# STM32C5A3 register map
File version: 2.1.0
CPU: CM33 r0p4, little endian, MPU, FPU, 4 interrupt priority bits
Registers are 32-bit, read-write, reset 0x0 unless marked. A register's access mark holds for its fields unless they carry their own. Offsets are from the block's base; [hi:lo] are bit positions; {n}, {i} and the like mark numbered series; 'fields as' and 'values as' point back to an identical list.

## RCC — RCC register block
Base 0x44020C00
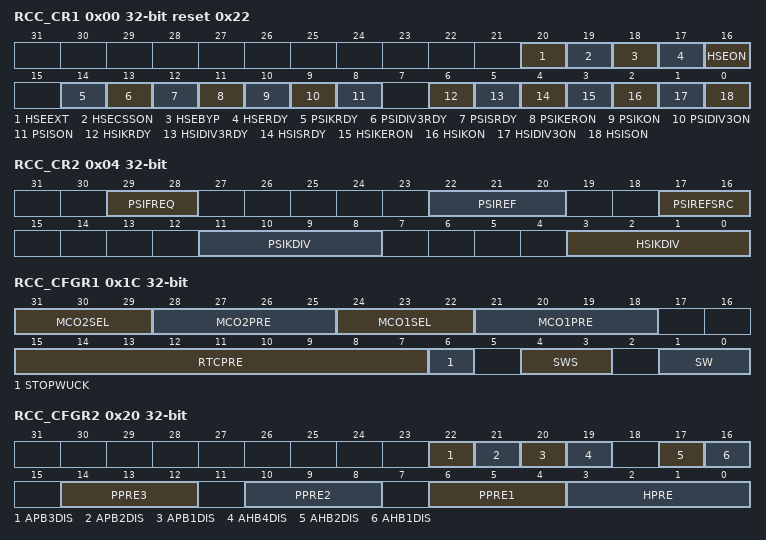
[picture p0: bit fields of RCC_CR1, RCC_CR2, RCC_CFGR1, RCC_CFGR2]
0x00 RCC_CR1 reset 0x22 — RCC clock control register
  [20] HSEEXT — External high speed clock type in Bypass mode
    0=HSE in analog mode (default after reset); 1=HSE in digital mode
  [19] HSECSSON — HSE clock security system enable
    0=CSS on HSE off (clock detector off) (default after reset); 1=CSS on HSE on (clock detector on if the HSE oscillator is stable, off if not)
  [18] HSEBYP — HSE clock bypass
    0=HSE oscillator not bypassed (default after reset); 1=HSE oscillator bypassed with an external clock
  [17] HSERDY ro — HSE clock ready flag
    0=HSE clock not ready (default after reset); 1=HSE clock ready
  [16] HSEON — HSE clock enable
    0=HSE off (default after reset); 1=HSE on
  [14] PSIKRDY ro — PSIK clock ready flag
    0=PSIK clock not ready (default after reset); 1=PSIK clock ready
  [13] PSIDIV3RDY ro — PSIDIV3 clock ready flag
    0=PSIDIV3 clock not ready (default after reset); 1=PSIDIV3 clock ready
  [12] PSISRDY ro — PSIS clock ready flag
    0=PSIS clock not ready (default after reset); 1=PSIS clock ready
  [11] PSIKERON — PSI clock enable in Stop mode
    0=No effect on PSI (default after reset); 1=PSI forced to on even in Stop 0 mode
  [10] PSIKON — PSIK clock enable
    0=PSIK off (default after reset); 1=PSIK on
  [9] PSIDIV3ON — PSIDIV3 clock enable
    0=PSIDIV3 off (default after reset); 1=PSIDIV3 on
  [8] PSISON — PSIS clock enable
    0=PSIS off (default after reset); 1=PSIS on
  [6] HSIKRDY ro — HSIK clock ready flag
    0=HSIK clock not ready (default after reset); 1=HSIK clock ready
  [5] HSIDIV3RDY ro — HSIDIV3 clock ready flag
    0=HSIDIV3 clock not ready (default after reset); 1=HSIDIV3 clock ready
  [4] HSISRDY ro — HSIS clock ready flag
    0=HSIS clock not ready (default after reset); 1=HSIS clock ready
  [3] HSIKERON — HSI clock enable in Stop mode
    0=No effect on HSI (default after reset); 1=HSI forced to on even in Stop 0 mode
  [2] HSIKON — HSIK clock enable
    0=HSIK off (default after reset); 1=HSIK on
  [1] HSIDIV3ON — HSIDIV3 clock enable
    0=HSIDIV3 off; 1=HSIDIV3 on (default after reset)
  [0] HSISON — HSIS clock enable
    0=HSIS off (default after reset); 1=HSIS on
0x04 RCC_CR2 — RCC clock control register
  [29:28] PSIFREQ — PSI target frequency configuration
    0=PSI nominal frequency = 100 MHz; 1=PSI nominal frequency = 144 MHz
  [22:20] PSIREF — PSI reference clock frequency selection
    0=32; 1=8 MHz; 2=16 MHz; 3=24 MHz; 4=25 MHz; 5=32 MHz; 6=48 MHz; 7=50 MHz
  [17:16] PSIREFSRC — PSI reference clock source selection
    0=HSE clock used as reference for PSI; 1=LSE clock used as reference for PSI; 2=HSI clock divided by 18 used as reference for PSI
  [11:8] PSIKDIV — PSI clock out divider factor
    0=PSI clock divided by 1; 1=PSI clock divided by 1; 2=PSI clock divided by 1; 3=PSI clock divided by 2; 4=PSI clock divided by 2; 14=PSI clock divided by 7; 15=PSI clock divided by 8
  [3:0] HSIKDIV — HSI clock out divider factor
    0=HSI clock divided by 1; 1=HSI clock divided by 1; 2=HSI clock divided by 1; 3=HSI clock divided by 2; 4=HSI clock divided by 2; 14=HSI clock divided by 7; 15=HSI clock divided by 8
0x1C RCC_CFGR1 — RCC clock configuration register1
  [31:29] MCO2SEL — Microcontroller clock output 2
    0=system clock selected (sys_ck) (default after reset); 1=HSE clock selected (hse_ck); 2=LSE clock selected (lse_ck); 3=LSI clock selected (lsi_ck); 4=PSIK clock selected (psik_ck); 5=HSIK clock selected (hsik_ck); 6=PSIDIV3 clock selected (psidiv3_ck); 7=HSIDIV3 clock selected (hsidiv3_ck)
  [28:25] MCO2PRE — MCO2 prescaler
    0=Prescaler disabled (default after reset); 1=Division by 1 (bypass); 2=Division by 2; 3=Division by 3; 4=Division by 4; 15=Division by 15
  [24:22] MCO1SEL — Microcontroller clock output 1
    0=System clock selected (sys_ck) (default after reset); 1=HSE clock selected (hse_ck); 2=LSE clock selected (lse_ck); 3=LSI clock selected (lsi_ck); 4=PSIK clock selected (psik_ck); 5=HSIK clock selected (hsik_ck); 6=PSIS clock selected (psis_ck); 7=HSIS clock selected (hsis_ck)
  [21:18] MCO1PRE — MCO1 prescaler
    values as MCO2PRE
  [15:7] RTCPRE — HSE division factor for RTC clock (source of HSE_1MHz clock)
    0=No clock (default after reset); 1=No clock; 2=HSE/2; 3=HSE/3; 4=HSE/4; 0x1FE=HSE/510; 0x1FF=HSE/511
  [6] STOPWUCK — System clock selection after a wake-up from system Stop mode
    0=HSIDIV3 selected as wake-up clock from system Stop mode (default after reset); 1=HSIS selected as wake-up clock from system Stop mode
  [4:3] SWS ro — System clock switch status
    0=HSIDIV3 used as system clock (hsidiv3_ck) (default after reset); 1=HSIS used as system clock (hsis_ck); 2=HSE used as system clock (hse_ck); 3=PSIS used as system clock (psis_ck)
  [1:0] SW — System clock and trace clock switch
    0=HSIDIV3 selected as system clock (hsidiv3_ck) (default after reset); 1=HSIS selected as system clock (hsis_ck); 2=HSE selected as system clock (hse_ck); 3=PSIS selected as system clock (psis_ck)
0x20 RCC_CFGR2 — RCC CPU domain clock configuration register 2
  [22] APB3DIS — APB3 clock disable value.
    0=APB3 clock enabled, distributed to peripherals according to their dedicated clock enable control bits; 1=APB3 clock disabled
  [21] APB2DIS — APB2 clock disable value
    0=APB2 clock enabled, distributed to peripherals according to their dedicated clock enable control bits; 1=APB2 clock disabled
  [20] APB1DIS — APB1 clock disable value
    0=APB1 clock enabled, distributed to peripherals according to their dedicated clock enable control bits; 1=APB1 clock disabled
  [19] AHB4DIS — AHB4 clock disable
    0=AHB4 clock enabled, distributed to peripherals according to their dedicated clock enable control bits; 1=AHB4 clock disabled
  [17] AHB2DIS — AHB2 clock disable
    0=AHB2 clock enabled, distributed to peripherals according to their dedicated clock enable control bits; 1=AHB2 clock disabled
  [16] AHB1DIS — AHB1 clock disable
    0=AHB1 clock enabled, distributed to peripherals according to their dedicated clock enable control bits; 1=AHB1 clock disabled
  [14:12] PPRE3 — APB low-speed prescaler (APB3)
    4=rcc_pclk3 = rcc_hclk1 / 2; 5=rcc_pclk3 = rcc_hclk1 / 4; 6=rcc_pclk3 = rcc_hclk1 / 8; 7=rcc_pclk3 = rcc_hclk1 / 16
  [10:8] PPRE2 — APB high-speed prescaler (APB2)
    4=rcc_pclk2 = rcc_hclk1 / 2; 5=rcc_pclk2 = rcc_hclk1 / 4; 6=rcc_pclk2 = rcc_hclk1 / 8; 7=rcc_pclk2 = rcc_hclk1 / 16
  [6:4] PPRE1 — APB low-speed prescaler (APB1)
    4=rcc_pclk1 = rcc_hclk1 / 2; 5=rcc_pclk1 = rcc_hclk1 / 4; 6=rcc_pclk1 = rcc_hclk1 / 8; 7=rcc_pclk1 = rcc_hclk1 / 16
  [3:0] HPRE — AHB prescaler
    8=rcc_hclk = sys_ck / 2; 9=rcc_hclk = sys_ck / 4; 10=rcc_hclk = sys_ck / 8; 11=rcc_hclk = sys_ck / 16; 12=rcc_hclk = sys_ck / 64; 13=rcc_hclk = sys_ck / 128; 14=rcc_hclk = sys_ck / 256; 15=rcc_hclk = sys_ck / 512
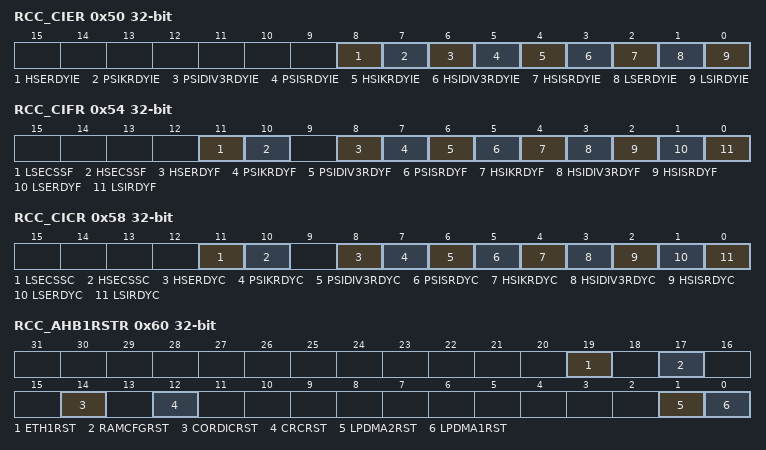
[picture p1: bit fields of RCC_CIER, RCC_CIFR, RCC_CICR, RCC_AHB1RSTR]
0x50 RCC_CIER — RCC clock source interrupt enable register
  [8] HSERDYIE — HSE ready interrupt enable
    0=HSE ready interrupt disabled (default after reset); 1=HSE ready interrupt enabled
  [7] PSIKRDYIE — PSIK ready interrupt enable
    0=PSIK ready interrupt disabled (default after reset); 1=PSIK ready interrupt enabled
  [6] PSIDIV3RDYIE — PSIDIV3 ready interrupt enable
    0=PSIDIV3 ready interrupt disabled (default after reset); 1=PSIDIV3 ready interrupt enabled
  [5] PSISRDYIE — PSIS ready interrupt enable
    0=PSI ready interrupt disabled (default after reset); 1=PSI ready interrupt enabled
  [4] HSIKRDYIE — HSIK ready interrupt enable
    0=HSIK ready interrupt disabled (default after reset); 1=HSIK ready interrupt enabled
  [3] HSIDIV3RDYIE — HSIDIV3 ready interrupt enable
    0=HSIDIV3 ready interrupt disabled (default after reset); 1=HSIDIV3 ready interrupt enabled
  [2] HSISRDYIE — HSIS ready interrupt enable
    0=HSI ready interrupt disabled (default after reset); 1=HSI ready interrupt enabled
  [1] LSERDYIE — LSE ready interrupt enable
    0=LSE ready interrupt disabled (default after reset); 1=LSE ready interrupt enabled
  [0] LSIRDYIE — LSI ready interrupt enable
    0=LSI ready interrupt disabled (default after reset); 1=LSI ready interrupt enabled
0x54 RCC_CIFR ro — RCC clock source interrupt flag register
  [11] LSECSSF — LSE clock security system interrupt flag
    0=No clock security interrupt caused by LSE clock failure (default after reset); 1=Clock security interrupt caused by LSE clock failure
  [10] HSECSSF — HSE clock security system interrupt flag
    0=No clock security interrupt caused by HSE clock failure (default after reset); 1=Clock security interrupt caused by HSE clock failure
  [8] HSERDYF — HSE ready interrupt flag
    0=No clock ready interrupt caused by the HSE (default after reset); 1=Clock ready interrupt caused by the HSE
  [7] PSIKRDYF — PSIK ready interrupt flag
    0=No clock ready interrupt caused by PSIK (default after reset); 1=Clock ready interrupt caused by PSIK
  [6] PSIDIV3RDYF — PSIDIV3 ready interrupt flag
    0=No clock ready interrupt caused by PSIDIV3 (default after reset); 1=Clock ready interrupt caused by PSIDIV3
  [5] PSISRDYF — PSIS ready interrupt flag
    0=No clock ready interrupt caused by PSIS (default after reset); 1=Clock ready interrupt caused by PSIS
  [4] HSIKRDYF — HSIK ready interrupt flag
    0=No clock ready interrupt caused by HSIK (default after reset); 1=Clock ready interrupt caused by HSIK
  [3] HSIDIV3RDYF — HSIDIV3 ready interrupt flag
    0=No clock ready interrupt caused by HSIDIV3 (default after reset); 1=Clock ready interrupt caused by HSIDIV3
  [2] HSISRDYF — HSIS ready interrupt flag
    0=No clock ready interrupt caused by HSIS (default after reset); 1=Clock ready interrupt caused by HSIS
  [1] LSERDYF — LSE ready interrupt flag
    0=No clock ready interrupt caused by the LSE (default after reset); 1=Clock ready interrupt caused by the LSE
  [0] LSIRDYF — LSI ready interrupt flag
    0=No clock ready interrupt caused by the LSI (default after reset); 1=Clock ready interrupt caused by the LSI
0x58 RCC_CICR — RCC clock source interrupt clear register
  [11] LSECSSC — LSE clock security system interrupt clear
    0=LSECSSF no effect (default after reset); 1=LSECSSF cleared
  [10] HSECSSC — HSE clock security system interrupt clear
    0=HSECSSF no effect (default after reset); 1=HSECSSF cleared
  [8] HSERDYC — HSE ready interrupt clear
    0=HSERDYF no effect (default after reset); 1=HSERDYF cleared
  [7] PSIKRDYC — PSIK ready interrupt clear
    0=PSIKRDYF no effect (default after reset); 1=PSIKRDYF cleared
  [6] PSIDIV3RDYC — PSIDIV3 ready interrupt clear
    0=PSIDIV3RDYF no effect (default after reset); 1=PSIDIV3RDYF cleared
  [5] PSISRDYC — PSIS ready interrupt clear
    0=PSISRDYF no effect (default after reset); 1=PSISRDYF cleared
  [4] HSIKRDYC — HSIK ready interrupt clear
    0=HSIKRDYF no effect (default after reset); 1=HSIKRDYF cleared
  [3] HSIDIV3RDYC — HSIDIV3 ready interrupt clear
    0=HSIDIV3RDYF no effect (default after reset); 1=HSIDIV3RDYF cleared
  [2] HSISRDYC — HSIS ready interrupt clear
    0=HSISRDYF no effect (default after reset); 1=HSISRDYF cleared
  [1] LSERDYC — LSE ready interrupt clear
    0=LSERDYF no effect (default after reset); 1=LSERDYF cleared
  [0] LSIRDYC — LSI ready interrupt clear
    0=LSIRDYF no effect (default after reset); 1=LSIRDYF cleared
0x60 RCC_AHB1RSTR — RCC AHB1 reset register
  [19] ETH1RST — ETHERNET reset
    0=ETHERNET not reset (default after reset); 1=ETHERNET reset
  [17] RAMCFGRST — RAMCFG reset
    0=RAMCFG not reset (default after reset); 1=RAMCFG reset
  [14] CORDICRST — CORDIC reset
    0=CORDIC not reset (default after reset); 1=CORDIC reset
  [12] CRCRST — CRC reset
    0=CRC not reset (default after reset); 1=CRC reset
  [1] LPDMA2RST — LPDMA2 reset
    0=LPDMA2 not reset (default after reset); 1=LPDMA2 reset
  [0] LPDMA1RST — LPDMA1 reset
    0=LPDMA1 not reset (default after reset); 1=LPDMA1 reset
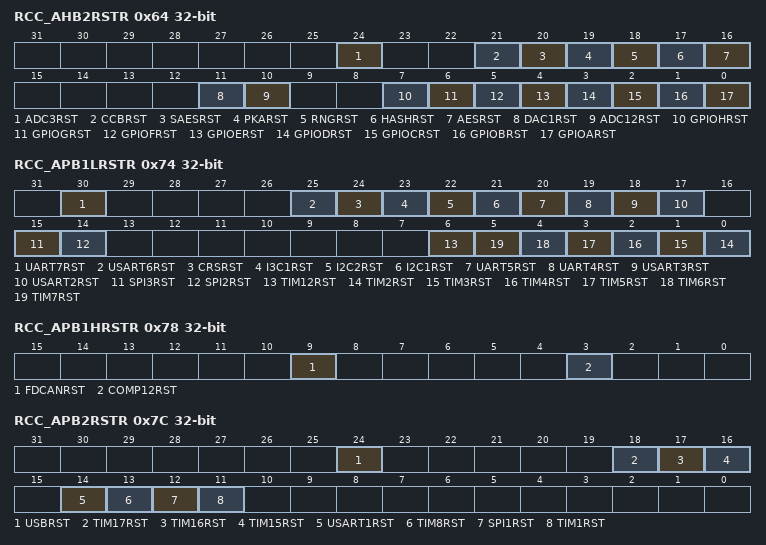
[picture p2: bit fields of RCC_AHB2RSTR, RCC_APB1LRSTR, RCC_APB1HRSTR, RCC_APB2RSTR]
0x64 RCC_AHB2RSTR — RCC AHB2 peripheral reset register
  [24] ADC3RST — ADC3 reset
    0=ADC3 not reset (default after reset); 1=ADC3 reset
  [21] CCBRST — CCB reset
    0=CCB not reset (default after reset); 1=CCB reset
  [20] SAESRST — SAES reset
    0=SAES not reset (default after reset); 1=SAES reset
  [19] PKARST — PKA reset
    0=PKA not reset (default after reset); 1=PKA reset
  [18] RNGRST — RNG reset
    0=RNG not reset (default after reset); 1=RNG reset
  [17] HASHRST — HASH reset
    0=HASH not reset (default after reset); 1=HASH reset
  [16] AESRST — AES reset
    0=AES not reset (default after reset); 1=AES reset
  [11] DAC1RST — DAC reset
    0=DAC not reset (default after reset); 1=DAC reset
  [10] ADC12RST — ADC1 and ADC2 reset
    0=ADC1 and ADC2 not reset (default after reset); 1=ADC1 and ADC2 reset
  [7] GPIOHRST — GPIOH reset
    0=GPIOH not reset (default after reset); 1=GPIOH reset
  [6] GPIOGRST — GPIOG reset
    0=GPIOG not reset (default after reset); 1=GPIOG reset
  [5] GPIOFRST — GPIOF reset
    0=GPIOF not reset (default after reset); 1=GPIOF reset
  [4] GPIOERST — GPIOE reset
    0=GPIOE not reset (default after reset); 1=GPIOE reset
  [3] GPIODRST — GPIOD reset
    0=e GPIOD not reset (default after reset); 1=GPIOD reset
  [2] GPIOCRST — GPIOC reset
    0=GPIOC not reset (default after reset); 1=GPIOC reset
  [1] GPIOBRST — GPIOB reset
    0=GPIOB not reset (default after reset); 1=GPIOB reset
  [0] GPIOARST — GPIOA reset
    0=GPIOA not reset (default after reset); 1=GPIOA reset
0x6C RCC_AHB4RSTR — RCC AHB4 peripheral reset register
  [20] XSPI1RST — XSPI1 reset
    0=XSPI1 not reset (default after reset); 1=XSPI1 reset
0x74 RCC_APB1LRSTR — RCC APB1 peripheral low reset register
  [30] UART7RST — UART7 reset
    0=UART7 not reset (default after reset); 1=UART7 reset
  [25] USART6RST — USART6 reset
    0=USART6 not reset (default after reset); 1=USART6 reset
  [24] CRSRST — CRS reset
    0=CRS not reset (default after reset); 1=CRS reset
  [23] I3C1RST — I3C1 block reset
    0=I3C1 not reset (default after reset); 1=I3C1 reset
  [22] I2C2RST — I2C2 reset
    0=I2C2 not reset (default after reset); 1=I2C2 reset
  [21] I2C1RST — I2C1 reset
    0=I2C1 not reset (default after reset); 1=I2C1 reset
  [20] UART5RST — UART5 reset
    0=UART5 not reset (default after reset); 1=UART5 reset
  [19] UART4RST — UART4 reset
    0=UART4 not reset (default after reset); 1=UART4 reset
  [18] USART3RST — USART3 reset
    0=USART3 not reset (default after reset); 1=USART3 reset
  [17] USART2RST — USART2 reset
    0=USART2 not reset (default after reset); 1=USART2 reset
  [15] SPI3RST — SPI3 reset
    0=SPI3 not reset (default after reset); 1=SPI3 reset
  [14] SPI2RST — SPI2 reset
    0=SPI2 not reset (default after reset); 1=SPI2 reset
  [6] TIM12RST — TIM12 reset
    0=TIM12 not reset (default after reset); 1=TIM12 reset
  [n-2] TIM{n}RST (n=2..7) — TIM{n} reset
    0=TIM{n} not reset (default after reset); 1=TIM{n} reset
0x78 RCC_APB1HRSTR — RCC APB1peripheral high reset register
  [9] FDCANRST — FDCAN1 and FDCAN2 reset
    0=FDCAN1 and FDCAN2 not reset (default after reset); 1=FDCAN1 and FDCAN2 reset
  [3] COMP12RST — COMP reset
    0=COMP not reset (default after reset); 1=COMP reset
0x7C RCC_APB2RSTR — RCC APB2 peripheral reset register
  [24] USBRST — USB reset
    0=USB not reset (default after reset); 1=USB reset
  [18] TIM17RST — TIM17 reset
    0=TIM17 not reset (default after reset); 1=TIM17 reset
  [17] TIM16RST — TIM16 reset
    0=TIM16 not reset (default after reset); 1=TIM16 reset
  [16] TIM15RST — TIM15 reset
    0=TIM15 not reset (default after reset); 1=TIM15 reset
  [14] USART1RST — USART1 reset
    0=USART1 not reset (default after reset); 1=USART1 reset
  [13] TIM8RST — TIM8 reset
    0=TIM8 not reset (default after reset); 1=TIM8 reset
  [12] SPI1RST — SPI1 reset
    0=SPI1 not reset (default after reset); 1=SPI1 reset
  [11] TIM1RST — TIM1 reset
    0=TIM1 not reset (default after reset); 1=TIM1 reset
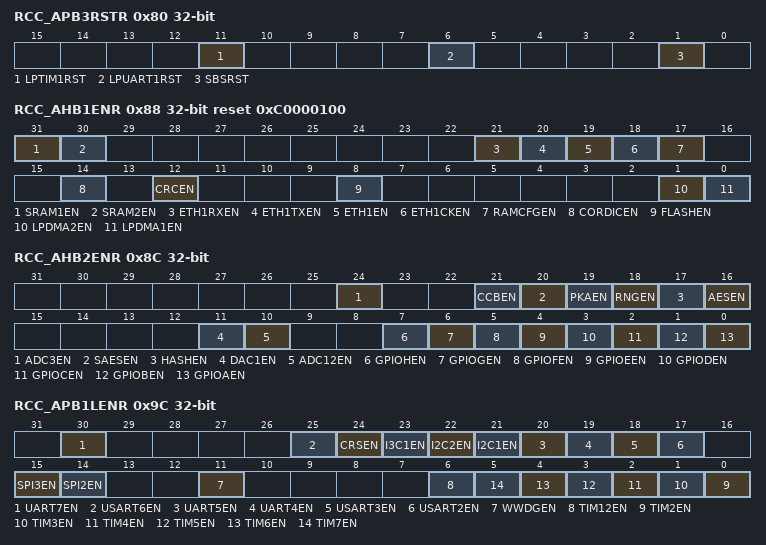
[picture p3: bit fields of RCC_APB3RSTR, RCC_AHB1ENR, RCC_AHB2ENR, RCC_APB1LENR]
0x80 RCC_APB3RSTR — RCC APB3 peripheral reset register
  [11] LPTIM1RST — LPTIM1 reset
    0=LPTIM1 not reset (default after reset); 1=LPTIM1 reset
  [6] LPUART1RST — LPUART1 reset
    0=LPUART1 not reset (default after reset); 1=LPUART1 reset
  [1] SBSRST — SBS reset
    0=SBS not reset (default after reset); 1=SBS reset
0x88 RCC_AHB1ENR reset 0xC0000100 — RCC AHB1 peripherals clock register
  [31] SRAM1EN — SRAM1 clock enable
    0=SRAM1 clock disabled; 1=SRAM1 clock enabled (default after reset)
  [30] SRAM2EN — SRAM2 clock enable
    0=SRAM2 clock disabled; 1=SRAM2 clock enabled (default after reset)
  [21] ETH1RXEN — ETHRX clock enable
    0=ETHRX clock disabled (default after reset); 1=ETHRX clock enabled
  [20] ETH1TXEN — ETHTX clock enable
    0=ETHTX clock disabled (default after reset); 1=ETHTX clock enabled
  [19] ETH1EN — ETH clock enable
    0=ETH clock disabled (default after reset); 1=ETH clock enabled
  [18] ETH1CKEN — ETH internal clock enable
    0=ETH internal clock disabled (default after reset); 1=ETH internal clock enabled
  [17] RAMCFGEN — RAMCFG clock enable
    0=RAMCFG clock disabled (default after reset); 1=RAMCFG clock enabled
  [14] CORDICEN — CORDIC clock enable
    0=CORDIC clock disabled (default after reset); 1=CORDIC clock enabled
  [12] CRCEN — CRC clock enable
    0=CRC clock disabled (default after reset); 1=CRC clock enabled
  [8] FLASHEN — Flash interface clock enable
    0=FLASH clock disabled; 1=FLASH clock enabled (default after reset)
  [1] LPDMA2EN — LPDMA2 clock enable
    0=LPDMA2 clock disabled (default after reset); 1=LPDMA2 clock enabled
  [0] LPDMA1EN — LPDMA1 clock enable
    0=LPDMA1 clock disabled (default after reset); 1=LPDMA1 clock enabled
0x8C RCC_AHB2ENR — RCC AHB2 peripheral clock register
  [24] ADC3EN — ADC3 clock enable
    0=ADC3 clock disabled (default after reset); 1=ADC3 clock enabled
  [21] CCBEN — CCB clock enable
    0=CCB clock disabled (default after reset); 1=CCB clock enabled
  [20] SAESEN — SAES clock enable
    0=SAES clock disabled (default after reset); 1=SAES clock enabled
  [19] PKAEN — PKA clock enable
    0=PKA clock disabled (default after reset); 1=PKA clock enabled
  [18] RNGEN — RNG clock enable
    0=RNG clock disabled (default after reset); 1=RNG clock enabled
  [17] HASHEN — HASH clock enable
    0=HASH clock disabled (default after reset); 1=HASH clock enabled
  [16] AESEN — AES clock enable
    0=AES clock disabled (default after reset); 1=AES clock enabled
  [11] DAC1EN — DAC clock enable
    0=DAC clock disabled (default after reset); 1=DAC clock enabled
  [10] ADC12EN — ADC1 and ADC2 clock enable
    0=ADC1 and ADC2 clock disabled (default after reset); 1=ADC1 and ADC2 clock enabled
  [7] GPIOHEN — GPIOH clock enable
    0=GPIOH clock disabled (default after reset); 1=GPIOH clock enabled
  [6] GPIOGEN — GPIOG clock enable
    0=GPIOG clock disabled (default after reset); 1=GPIOG clock enabled
  [5] GPIOFEN — GPIOF clock enable
    0=GPIOF clock disabled (default after reset); 1=GPIOF clock enabled
  [4] GPIOEEN — GPIOE clock enable
    0=GPIOE clock disabled (default after reset); 1=GPIOE clock enabled
  [3] GPIODEN — GPIOD clock enable
    0=GPIOD clock disabled (default after reset); 1=GPIOD clock enabled
  [2] GPIOCEN — GPIOC clock enable
    0=GPIOC clock disabled (default after reset); 1=GPIOC clock enabled
  [1] GPIOBEN — GPIOB clock enable
    0=GPIOB clock disabled (default after reset); 1=GPIOB clock enabled
  [0] GPIOAEN — GPIOA clock enable
    0=GPIOA clock disabled (default after reset); 1=GPIOA clock enabled
0x94 RCC_AHB4ENR — RCC AHB4 peripheral clock register
  [20] XSPI1EN — XSPI1 clock enable
    0=XSPI1 peripheral clock disabled; 1=XSPI1 peripheral clock enabled
0x9C RCC_APB1LENR — RCC APB1 peripheral clock register
  [30] UART7EN — UART7 clock enable
    0=UART7 clock disabled (default after reset); 1=UART7 clock enabled
  [25] USART6EN — USART6 clock enable
    0=USART6 clock disabled (default after reset); 1=USART6 clock enabled
  [24] CRSEN — CRS clock enable
    0=CRS clock disabled (default after reset); 1=CRS clock enabled
  [23] I3C1EN — I3C1 clock enable
    0=I3C1 clock disabled (default after reset); 1=I3C1 clock enabled
  [22] I2C2EN — I2C2 clock enable
    0=I2C2 clock disabled (default after reset); 1=I2C2 clock enabled
  [21] I2C1EN — I2C1 clock enable
    0=I2C1 clock disabled (default after reset); 1=I2C1 clock enabled
  [20] UART5EN — UART5 clock enable
    0=UART5 clock disabled (default after reset); 1=UART5 clock enabled
  [19] UART4EN — UART4 clock enable
    0=UART4 clock disabled (default after reset); 1=UART4 clock enabled
  [18] USART3EN — USART3 clock enable
    0=USART3 clock disabled (default after reset); 1=USART3 clock enabled
  [17] USART2EN — USART2 clock enable
    0=USART2 clock disabled (default after reset); 1=USART2 clock enabled
  [15] SPI3EN — SPI3 clock enable
    0=SPI3 clock disabled (default after reset); 1=SPI3 clock enabled
  [14] SPI2EN — SPI2 clock enable
    0=SPI2 clock disabled (default after reset); 1=SPI2 clock enabled
  [11] WWDGEN — WWDG clock enable
    0=WWDG clock disabled (default after reset); 1=WWDG clock enabled
  [6] TIM12EN — TIM12 clock enable
    0=TIM12 clock disabled (default after reset); 1=TIM12 clock enabled
  [n-2] TIM{n}EN (n=2..7) — TIM{n} clock enable
    0=TIM{n} clock disabled (default after reset); 1=TIM{n} clock enabled
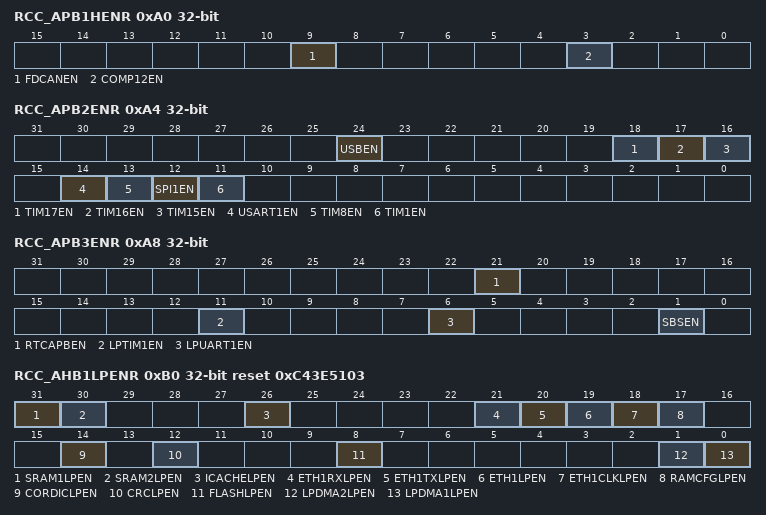
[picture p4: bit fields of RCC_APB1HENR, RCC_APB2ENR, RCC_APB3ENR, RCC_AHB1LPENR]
0xA0 RCC_APB1HENR — RCC APB1 peripheral clock register
  [9] FDCANEN — FDCAN1 and FDCAN2 clock enable
    0=FDCAN1 and FDCAN2 clock disabled (default after reset); 1=FDCAN1 and FDCAN2 clock enabled
  [3] COMP12EN — COMP clock enable
    0=COMP clock disabled (default after reset); 1=COMP clock enabled
0xA4 RCC_APB2ENR — RCC APB2 peripheral clock register
  [24] USBEN — USB clock enable
    0=USB clock disabled (default after reset); 1=USB clock enabled
  [18] TIM17EN — TIM17 clock enable
    0=TIM17 clock disabled (default after reset); 1=TIM17 clock enabled
  [17] TIM16EN — TIM16 clock enable
    0=TIM16 clock disabled (default after reset); 1=TIM16 clock enabled
  [16] TIM15EN — TIM15 clock enable
    0=TIM15 clock disabled (default after reset); 1=TIM15 clock enabled
  [14] USART1EN — USART1 clock enable
    0=USART1 clock disabled (default after reset); 1=USART1 clock enabled
  [13] TIM8EN — TIM8 clock enable
    0=TIM8 clock disabled (default after reset); 1=TIM8 clock enabled
  [12] SPI1EN — SPI1 clock enable
    0=SPI1 clock disabled (default after reset); 1=SPI1 clock enabled
  [11] TIM1EN — TIM1 clock enable
    0=TIM1 clock disabled (default after reset); 1=TIM1 clock enabled
0xA8 RCC_APB3ENR — RCC APB3 peripheral clock register
  [21] RTCAPBEN — RTC APB interface clock enable
    0=RTC APB interface clock disabled (default after reset); 1=RTC APB interface clock enabled
  [11] LPTIM1EN — LPTIM1 clock enable
    0=LPTIM1 clock disabled (default after reset); 1=LPTIM1 clock enabled
  [6] LPUART1EN — LPUART1 clock enable
    0=LPUART1 clock disabled (default after reset); 1=LPUART1 clock enabled
  [1] SBSEN — SBS clock enable
    0=SBS clock disabled (default after reset); 1=SBS clock enabled
0xB0 RCC_AHB1LPENR reset 0xC43E5103 — RCC AHB1 sleep clock register
  [31] SRAM1LPEN — SRAM1 clock enable during Sleep mode
    0=SRAM1 clock disabled during Sleep mode; 1=SRAM1 clock enabled during Sleep mode (default after reset)
  [30] SRAM2LPEN — SRAM2 clock enable during Sleep mode
    0=SRAM2 clock disabled during Sleep mode; 1=SRAM2 clock enabled during Sleep mode (default after reset)
  [26] ICACHELPEN — ICACHE clock enable during Sleep mode
    0=ICACHE clock disabled during Sleep mode; 1=ICACHE clock enabled during Sleep mode (default after reset)
  [21] ETH1RXLPEN — ETHRX clock enable during Sleep mode
    0=ETHRX clock disabled during Sleep mode; 1=ETHRX clock enabled during Sleep mode (default after reset)
  [20] ETH1TXLPEN — ETHTX clock enable during Sleep mode
    0=ETHTX clock disabled during Sleep mode; 1=ETHTX clock enabled during Sleep mode (default after reset)
  [19] ETH1LPEN — ETH clock enable during Sleep mode
    0=ETH clock disabled during Sleep mode; 1=ETH clock enabled during Sleep mode (default after reset)
  [18] ETH1CLKLPEN — ETH internal clock enable during Sleep mode
    0=ETH internal clock disabled during Sleep mode; 1=ETH internal clock enabled during Sleep mode (default after reset)
  [17] RAMCFGLPEN — RAMCFG clock enable during Sleep mode
    0=RAMCFG clock disabled during Sleep mode; 1=RAMCFG clock enabled during Sleep mode (default after reset)
  [14] CORDICLPEN — CORDIC clock enable during Sleep mode
    0=CORDIC clock disabled during Sleep mode; 1=CORDIC clock enabled during Sleep mode (default after reset)
  [12] CRCLPEN — CRC clock enable during Sleep mode
    0=CRC clock disabled during Sleep mode; 1=CRC clock enabled during Sleep mode (default after reset)
  [8] FLASHLPEN — Flash interface clock enable during Sleep mode
    0=FLASH clock disabled during Sleep mode; 1=FLASH clock enabled during Sleep mode (default after reset)
  [1] LPDMA2LPEN — LPDMA2 clock enable during Sleep mode
    0=LPDMA2 clock disabled during Sleep mode; 1=LPDMA2 clock enabled during Sleep mode (default after reset)
  [0] LPDMA1LPEN — LPDMA1 clock enable during Sleep mode
    0=LPDMA1 clock disabled during Sleep mode; 1=LPDMA1 clock enabled during Sleep mode (default after reset)
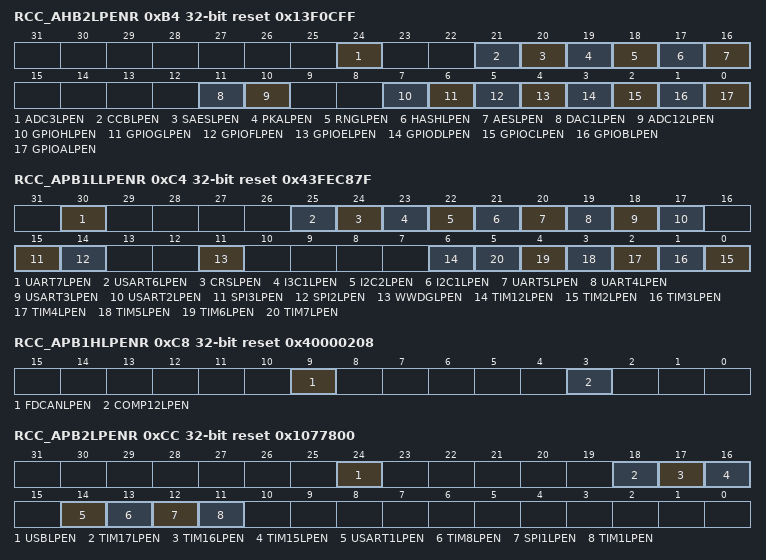
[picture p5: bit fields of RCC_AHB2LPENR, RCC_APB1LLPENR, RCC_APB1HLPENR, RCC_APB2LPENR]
0xB4 RCC_AHB2LPENR reset 0x13F0CFF — RCC AHB2 sleep clock register
  [24] ADC3LPEN — ADC3 clock enable during Sleep mode
    0=ADC3 clock disabled during Sleep mode; 1=ADC3 clock enabled during Sleep mode (default after reset)
  [21] CCBLPEN — CCB clock enable during Sleep mode
    0=CCB clock disabled during Sleep mode; 1=CCB clock enabled during Sleep mode (default after reset)
  [20] SAESLPEN — SAES clock enable during Sleep mode
    0=SAES clock disabled during Sleep mode; 1=SAES clock enabled during Sleep mode (default after reset)
  [19] PKALPEN — PKA clock enable during Sleep mode
    0=PKA clock disabled during Sleep mode; 1=PKA clock enabled during Sleep mode (default after reset)
  [18] RNGLPEN — RNG clock enable during Sleep mode
    0=RNG clock disabled during Sleep mode; 1=RNG clock enabled during Sleep mode (default after reset)
  [17] HASHLPEN — HASH clock enable during Sleep mode
    0=HASH clock disabled during Sleep mode; 1=HASH clock enabled during Sleep mode (default after reset)
  [16] AESLPEN — AES clock enable during Sleep mode
    0=AES clock disabled during Sleep mode; 1=AES clock enabled during Sleep mode (default after reset)
  [11] DAC1LPEN — DAC clock enable during Sleep mode
    0=DAC clock disabled during Sleep mode; 1=DAC clock enabled during Sleep mode (default after reset)
  [10] ADC12LPEN — ADC1 and ADC2 clock enable during Sleep mode
    0=ADC1 and ADC2 clock disabled during Sleep mode; 1=ADC1 and ADC2 clock enabled during Sleep mode (default after reset)
  [7] GPIOHLPEN — GPIOH clock enable during Sleep mode
    0=GPIOH clock disabled during Sleep mode; 1=GPIOH clock enabled during Sleep mode (default after reset)
  [6] GPIOGLPEN — GPIOG clock enable during Sleep mode
    0=GPIOG clock disabled during Sleep mode; 1=GPIOG clock enabled during Sleep mode (default after reset)
  [5] GPIOFLPEN — GPIOF clock enable during Sleep mode
    0=GPIOF clock disabled during Sleep mode; 1=GPIOF clock enabled during Sleep mode (default after reset)
  [4] GPIOELPEN — GPIOE clock enable during Sleep mode
    0=GPIOE clock disabled during Sleep mode; 1=GPIOE clock enabled during Sleep mode (default after reset)
  [3] GPIODLPEN — GPIOD clock enable during Sleep mode
    0=GPIOD clock disabled during Sleep mode; 1=GPIOD clock enabled during Sleep mode (default after reset)
  [2] GPIOCLPEN — GPIOC clock enable during Sleep mode
    0=GPIOC clock disabled during Sleep mode; 1=GPIOC clock enabled during Sleep mode (default after reset)
  [1] GPIOBLPEN — GPIOB clock enable during Sleep mode
    0=GPIOB clock disabled during Sleep mode; 1=GPIOB clock enabled during Sleep mode (default after reset)
  [0] GPIOALPEN — GPIOA clock enable during Sleep mode
    0=GPIOA clock disabled during Sleep mode; 1=GPIOA clock enabled during Sleep mode (default after reset)
0xBC RCC_AHB4LPENR reset 0x100000 — RCC AHB4 peripheral sleep clock register
  [20] XSPI1LPEN — XSPI1 clock enable during sleep mode
    0=XSPI1 clock disabled during sleep mode; 1=XSPI1 clock enabled during sleep mode (default after reset)
0xC4 RCC_APB1LLPENR reset 0x43FEC87F — RCC APB1 sleep clock register
  [30] UART7LPEN — UART7 clock enable during Sleep mode
    0=UART7 clock disabled during Sleep mode; 1=UART7 clock enabled during Sleep mode (default after reset)
  [25] USART6LPEN — USART6 clock enable during Sleep mode
    0=USART6 clock disabled during Sleep mode; 1=USART6 clock enabled during Sleep mode (default after reset)
  [24] CRSLPEN — CRS clock enable during Sleep mode
    0=CRS clock disabled during Sleep mode; 1=CRS clock enabled during Sleep mode (default after reset)
  [23] I3C1LPEN — I3C1 clock enable during Sleep mode
    0=I3C1 clock disabled during Sleep mode; 1=I3C1 clock enabled during Sleep mode (default after reset)
  [22] I2C2LPEN — I2C2 clock enable during Sleep mode
    0=I2C2 clock disabled during Sleep mode; 1=I2C2 clock enabled during Sleep mode (default after reset)
  [21] I2C1LPEN — I2C1 clock enable during Sleep mode
    0=I2C1 clock disabled during Sleep mode; 1=I2C1 clock enabled during Sleep mode (default after reset)
  [20] UART5LPEN — UART5 clock enable during Sleep mode
    0=UART5 clock disabled during Sleep mode; 1=UART5 clock enabled during Sleep mode (default after reset)
  [19] UART4LPEN — UART4 clock enable during Sleep mode
    0=UART4 clock disabled during Sleep mode; 1=UART4 clock enabled during Sleep mode (default after reset)
  [18] USART3LPEN — USART3 clock enable during Sleep mode
    0=USART3 clock disabled during Sleep mode; 1=USART3 clock enabled during Sleep mode (default after reset)
  [17] USART2LPEN — USART2 clock enable during Sleep mode
    0=USART2 clock disabled during Sleep mode; 1=USART2 clock enabled during Sleep mode (default after reset)
  [15] SPI3LPEN — SPI3 clock enable during Sleep mode
    0=SPI3 clock disabled during Sleep mode; 1=SPI3 clock enabled during Sleep mode (default after reset)
  [14] SPI2LPEN — SPI2 clock enable during Sleep mode
    0=SPI2 clock disabled during Sleep mode; 1=SPI2 clock enabled during Sleep mode (default after reset)
  [11] WWDGLPEN — WWDG clock enable during Sleep mode
    0=WWDG clock disabled during Sleep mode; 1=WWDG clock enabled during Sleep mode (default after reset)
  [6] TIM12LPEN — TIM12 clock enable during Sleep mode
    0=TIM12 clock disabled during Sleep mode; 1=TIM12 clock enabled during Sleep mode (default after reset)
  [n-2] TIM{n}LPEN (n=2..7) — TIM{n} clock enable during Sleep mode
    0=TIM{n} clock disabled during Sleep mode; 1=TIM{n} clock enabled during Sleep mode (default after reset)
0xC8 RCC_APB1HLPENR reset 0x40000208 — RCC APB1 sleep clock register
  [9] FDCANLPEN — FDCAN1 and FDCAN2 clock enable during Sleep mode
    0=FDCAN1 and FDCAN2 clock disabled during Sleep mode; 1=FDCAN1 and FDCAN2 clock enabled during Sleep mode (default after reset)
  [3] COMP12LPEN — COMP clock enable during Sleep mode
    0=COMP clock disabled during Sleep mode; 1=COMP clock enabled during Sleep mode (default after reset)
0xCC RCC_APB2LPENR reset 0x1077800 — RCC APB2 sleep clock register
  [24] USBLPEN — USB clock enable during Sleep mode
    0=USB clock disabled during Sleep mode; 1=USB clock enabled during Sleep mode (default after reset)
  [18] TIM17LPEN — TIM17 clock enable during Sleep mode
    0=TIM17 clock disabled during Sleep mode; 1=TIM17 clock enabled during Sleep mode (default after reset)
  [17] TIM16LPEN — TIM16 clock enable during Sleep mode
    0=TIM16 clock disabled during Sleep mode; 1=TIM16 clock enabled during Sleep mode (default after reset)
  [16] TIM15LPEN — TIM15 clock enable during Sleep mode
    0=TIM15 clock disabled during Sleep mode; 1=TIM15 clock enabled during Sleep mode (default after reset)
  [14] USART1LPEN — USART1 clock enable during Sleep mode
    0=USART1 clock disabled during Sleep mode; 1=USART1 clock enabled during Sleep mode (default after reset)
  [13] TIM8LPEN — TIM8 clock enable during Sleep mode
    0=TIM8 clock disabled during Sleep mode; 1=TIM8 clock enabled during Sleep mode (default after reset)
  [12] SPI1LPEN — SPI1 clock enable during Sleep mode
    0=SPI1 clock disabled during Sleep mode; 1=SPI1 clock enabled during Sleep mode (default after reset)
  [11] TIM1LPEN — TIM1 clock enable during Sleep mode
    0=TIM1 clock disabled during Sleep mode; 1=TIM1 clock enabled during Sleep mode (default after reset)
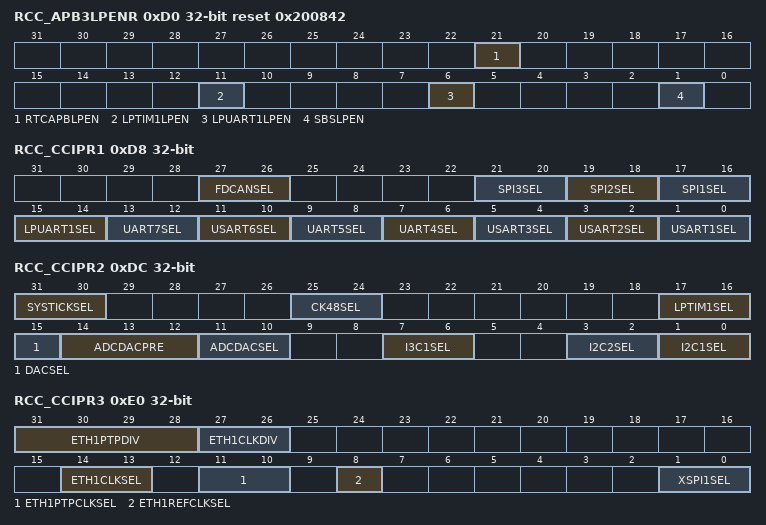
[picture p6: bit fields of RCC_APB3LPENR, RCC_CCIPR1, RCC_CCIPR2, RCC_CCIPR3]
0xD0 RCC_APB3LPENR reset 0x200842 — RCC APB3 sleep clock register
  [21] RTCAPBLPEN — RTC APB interface clock enable during Sleep mode
    0=RTC APB interface clock disabled during Sleep mode; 1=RTC APB interface clock enabled during Sleep mode (default after reset)
  [11] LPTIM1LPEN — LPTIM1 clock enable during Sleep mode
    0=LPTIM1 clock disabled during Sleep mode; 1=LPTIM1 clock enabled during Sleep mode (default after reset)
  [6] LPUART1LPEN — LPUART1 clock enable during Sleep mode
    0=LPUART1 clock disabled during Sleep mode; 1=LPUART1 clock enabled during Sleep mode (default after reset)
  [1] SBSLPEN — SBS clock enable during Sleep mode
    0=SBS clock disabled during Sleep mode; 1=SBS clock enabled during Sleep mode (default after reset)
0xD8 RCC_CCIPR1 — RCC kernel clock configuration register
  [27:26] FDCANSEL — FDCAN1 and FDCAN2 kernel clock source selection
    0=rcc_pclk1 selected as kernel clock (default after reset); 1=psis_ck selected as kernel clock; 2=psik_ck selected as kernel clock; 3=hse_ck selected as kernel clock
  [21:20] SPI3SEL — SPI3 kernel clock source selection
    0=rcc_pclk1 selected as kernel clock (default after reset); 1=psik_ck selected as kernel clock; 2=hsik_ck selected as kernel clock; 3=AUDIOCLK selected as kernel clock
  [19:18] SPI2SEL — SPI2 kernel clock source selection
    values as SPI3SEL
  [17:16] SPI1SEL — SPI1 kernel clock source selection
    0=rcc_pclk2 selected as kernel clock (default after reset); 1=psik_ck selected as kernel clock; 2=hsik_ck selected as kernel clock; 3=AUDIOCLK selected as kernel clock
  [15:14] LPUART1SEL — LPUART1 kernel clock source selection
    0=rcc_pclk3 selected as kernel clock (default after reset); 1=hsik_ck selected as kernel clock; 2=lse_ck selected as kernel clock; 3=lsi_ck selected as kernel clock
  [13:12] UART7SEL — UART7 kernel clock source selection
    0=rcc_pclk1 selected as kernel clock (default after reset); 1=psik_ck selected as kernel clock; 2=hsik_ck selected as kernel clock; 3=lse_ck selected as kernel clock
  [11:10] USART6SEL — USART6 kernel clock source selection
    values as UART7SEL
  [9:8] UART5SEL — UART5 kernel clock source selection
    values as UART7SEL
  [7:6] UART4SEL — UART4 kernel clock source selection
    values as UART7SEL
  [5:4] USART3SEL — UART3 kernel clock source selection
    values as UART7SEL
  [3:2] USART2SEL — USART2 kernel clock source selection
    values as UART7SEL
  [1:0] USART1SEL — USART1 kernel clock source selection
    0=rcc_pclk2 selected as kernel clock (default after reset); 1=psik_ck selected as kernel clock; 2=hsik_ck selected as kernel clock; 3=lse_ck selected as kernel clock
0xDC RCC_CCIPR2 — RCC kernel clock configuration register
  [31:30] SYSTICKSEL — SYSTICK clock source selection
    0=rcc_hclk/8 selected as clock source (default after reset); 1=lsi_ker_ck[1] selected as clock source; 2=lse_ck[1] selected as clock source
  [25:24] CK48SEL — CK48 clock source selection
    1=psi_div_3_ck selected as kernel clock; 2=hsi_div_3_ck selected as kernel clock; 3=hse_ck selected as kernel clock
  [17:16] LPTIM1SEL — LPTIM1 kernel clock source selection
    values as RCC_CCIPR1.LPUART1SEL
  [15] DACSEL — DAC sample and hold clock
    0=lse_ck selected as sample and hold clock (default after reset); 1=lsi_ck selected as sample and hold clock
  [14:12] ADCDACPRE — ADC and DAC prescaler for kernel clock source selection
    0=ADC and DAC kernel clock are not divided (default after reset); 1=ADC and DAC kernel clock divided by 2; 2=ADC and DAC kernel clock divided by 4; {v}=ADC and DAC kernel clock divided by {v} (v=3..7)
  [11:10] ADCDACSEL — ADC and DAC kernel clock source selection
    0=rcc_hclk selected as kernel clock; 1=psis_ck selected as kernel clock (default after reset); 2=psik_ck selected as kernel clock; 3=hsik_ck selected as kernel clock
  [7:6] I3C1SEL — I3C1 kernel clock source selection
    0=rcc_pclk1 selected as kernel clock (default after reset); 1=psik_ck selected as kernel clock; 2=hsik_ck selected as kernel clock
  [3:2] I2C2SEL — I2C2 kernel clock source selection
    values as I3C1SEL
  [1:0] I2C1SEL — I2C1 kernel clock source selection
    values as I3C1SEL
0xE0 RCC_CCIPR3 — RCC kernel clock configuration register
  [31:28] ETH1PTPDIV — Ethernet PTP clock division
    0=divided by 1(default after reset); {v}=divided by {v+1} (v=1..15)
  [27:26] ETH1CLKDIV — Ethernet clock division
    0=divided by 1(default after reset); 1=divided by 2; 2=divided by 4
  [14:13] ETH1CLKSEL — ETH clock source selection
    1=psis_ck selected as kernel clock; 2=psik_ck selected as kernel clock; 3=hse_ck selected as kernel clock
  [11:10] ETH1PTPCLKSEL — ETH PTP clock source selection
    1=rcc_hclk1 selected as kernel clock; 2=psis_ck selected as kernel clock; 3=psik_ck selected as kernel clock
  [8] ETH1REFCLKSEL — ETH RMII reference clock source selection
    0=ETH_RMII_REF_CLK (default after reset); 1=eth_clk_fb
  [1:0] XSPI1SEL — XSPI1 kernel clock source selection
    0=rcc_hclk4 selected as kernel clock (default after reset); 1=psik_ck selected as kernel clock; 2=hsik_ck selected as kernel clock
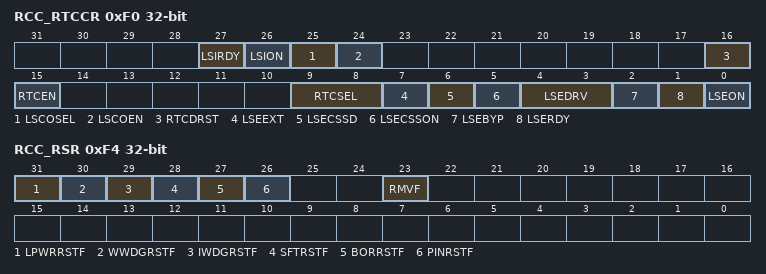
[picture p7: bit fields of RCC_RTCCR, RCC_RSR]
0xF0 RCC_RTCCR — RCC RTC domain control register
  [27] LSIRDY ro — LSI oscillator ready
    0=LSI oscillator not ready; 1=LSI oscillator ready
  [26] LSION — LSI oscillator enable
    0=LSI oscillator off; 1=LSI oscillator on
  [25] LSCOSEL — Low-speed clock output selection
    0=LSI clock selected; 1=LSE clock selected
  [24] LSCOEN — Low-speed clock output (LSCO) enable
    0=LSCO output disabled; 1=LSCO output enabled
  [16] RTCDRST — RTC domain software reset
    0=reset not activated (default after backup domain reset); 1=resets the entire VSW domain
  [15] RTCEN — RTC clock enable
    0=rtc_ck disabled (default after backup domain reset); 1=rtc_ck enabled
  [9:8] RTCSEL — RTC clock source selection
    0=No clock (default after backup domain reset); 1=LSE selected as RTC clock; 2=LSI selected as RTC clock; 3=HSE divided by RTCPRE value selected as RTC clock
  [7] LSEEXT — Low-speed external clock type in bypass mode
    0=LSE in analog mode (default after backup domain reset); 1=LSE in digital mode (do not use if RTC is active)
  [6] LSECSSD ro — LSE clock security system failure detection
    0=No failure detected on 32 kHz oscillator (default after backup domain reset); 1=Failure detected on 32 kHz oscillator
  [5] LSECSSON — LSE clock security system enable
    0=CSS on 32 kHz oscillator off (default after backup domain reset); 1=CSS on 32 kHz oscillator on
  [4:3] LSEDRV — LSE oscillator driving capability
    0=Lowest drive (default after backup domain reset); 1=Medium-low drive; 2=Medium-high drive; 3=Highest drive
  [2] LSEBYP — LSE oscillator bypass
    0=LSE oscillator not bypassed (default after backup domain reset); 1=LSE oscillator bypassed
  [1] LSERDY ro — LSE oscillator ready
    0=LSE oscillator not ready (default after backup domain reset); 1=LSE oscillator ready
  [0] LSEON — LSE oscillator enabled
    0=LSE oscillator off (default after backup domain reset); 1=LSE oscillator on
0xF4 RCC_RSR (reset mask 0xFFFFFF) — RCC reset status register
  [31] LPWRRSTF ro — Low-power reset flag
    0=No illegal low-power mode reset occurred; 1=An illegal low-power mode reset occurred
  [30] WWDGRSTF ro — Window watchdog reset flag
    0=No WWDG reset occurred (default after power-on reset); 1=A WWDG reset occurred
  [29] IWDGRSTF ro — Independent watchdog reset flag
    0=No IWDG reset occurred (default after power-on reset); 1=An IWDG reset occurred
  [28] SFTRSTF ro — System reset from CPU reset flag
    0=No CPU software reset occurred (default after power-on reset); 1=A system reset has been generated by the CPU
  [27] BORRSTF ro — POR reset flag
    0=No POR reset occurred; 1=A POR reset occurred (default after power-on reset)
  [26] PINRSTF ro — Pin reset flag (NRST)
    0=No reset from pin occurred; 1=A reset from pin occurred (default after power-on reset)
  [23] RMVF wo — Remove reset flag
    0=Reset of the reset flags not activated (default after power-on reset); 1=Reset the value of the reset flags
0x114 RCC_PRIVCFGR — RCC privilege configuration register
  [1] PRIV — RCC function privileged configuration
    0=Read and write to RCC functions can be done by privileged or unprivileged access; 1=Read and write to RCC functions can be done by privileged access only
